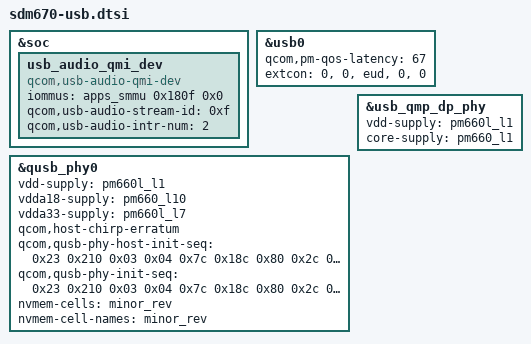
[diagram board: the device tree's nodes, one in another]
/*
 * Copyright (c) 2017-2018, The Linux Foundation. All rights reserved.
 *
 * This program is free software; you can redistribute it and/or modify
 * it under the terms of the GNU General Public License version 2 and
 * only version 2 as published by the Free Software Foundation.
 *
 * This program is distributed in the hope that it will be useful,
 * but WITHOUT ANY WARRANTY; without even the implied warranty of
 * MERCHANTABILITY or FITNESS FOR A PARTICULAR PURPOSE.  See the
 * GNU General Public License for more details.
 */

#include "sdm845-670-usb-common.dtsi"

&soc {
	/delete-node/ ssusb@a800000;
	/delete-node/ qusb@88e3000;
	/delete-node/ ssphy@88eb000;
	/delete-node/ usb_audio_qmi_dev;
	usb_audio_qmi_dev {
		compatible = "qcom,usb-audio-qmi-dev";
		iommus = <&apps_smmu 0x180f 0x0>;
		qcom,usb-audio-stream-id = <0xf>;
		qcom,usb-audio-intr-num = <2>;
	};
};

&usb0 {
	qcom,pm-qos-latency = <67>; /* CPU WFI latency + 1 */
	extcon = <0>, <0>, <&eud>, <0>, <0>;
};

&qusb_phy0 {
	vdd-supply = <&pm660l_l1>;
	vdda18-supply = <&pm660_l10>;
	vdda33-supply = <&pm660l_l7>;
	qcom,host-chirp-erratum;
	qcom,qusb-phy-host-init-seq =
			/* <value reg_offset> */
			   <0x23 0x210 /* PWR_CTRL1 */
			    0x03 0x04  /* PLL_ANALOG_CONTROLS_TWO */
			    0x7c 0x18c /* PLL_CLOCK_INVERTERS */
			    0x80 0x2c  /* PLL_CMODE */
			    0x0a 0x184 /* PLL_LOCK_DELAY */
			    0x19 0xb4  /* PLL_DIGITAL_TIMERS_TWO */
			    0x40 0x194 /* PLL_BIAS_CONTROL_1 */
			    0x20 0x198 /* PLL_BIAS_CONTROL_2 */
			    0x21 0x214 /* PWR_CTRL2 */
			    0x08 0x220 /* IMP_CTRL1 */
			    0x58 0x224 /* IMP_CTRL2 */
			    0x45 0x240 /* TUNE1 */
			    0x29 0x244 /* TUNE2 */
			    0xca 0x248 /* TUNE3 */
			    0x04 0x24c /* TUNE4 */
			    0x03 0x250 /* TUNE5 */
			    0x00 0x23c /* CHG_CTRL2 */
			    0x22 0x210>; /* PWR_CTRL1 */
	qcom,qusb-phy-init-seq =
			/* <value reg_offset> */
			   <0x23 0x210 /* PWR_CTRL1 */
			    0x03 0x04  /* PLL_ANALOG_CONTROLS_TWO */
			    0x7c 0x18c /* PLL_CLOCK_INVERTERS */
			    0x80 0x2c  /* PLL_CMODE */
			    0x0a 0x184 /* PLL_LOCK_DELAY */
			    0x19 0xb4  /* PLL_DIGITAL_TIMERS_TWO */
			    0x40 0x194 /* PLL_BIAS_CONTROL_1 */
			    0x20 0x198 /* PLL_BIAS_CONTROL_2 */
			    0x21 0x214 /* PWR_CTRL2 */
			    0x08 0x220 /* IMP_CTRL1 */
			    0x58 0x224 /* IMP_CTRL2 */
			    0x45 0x240 /* TUNE1 */
			    0x29 0x244 /* TUNE2 */
			    0xca 0x248 /* TUNE3 */
			    0x04 0x24c /* TUNE4 */
			    0x03 0x250 /* TUNE5 */
			    0x00 0x23c /* CHG_CTRL2 */
			    0x22 0x210>; /* PWR_CTRL1 */
	nvmem-cells = <&minor_rev>;
	nvmem-cell-names = "minor_rev";
};

&usb_qmp_dp_phy {
	vdd-supply = <&pm660l_l1>; /* 0.88v */
	core-supply = <&pm660_l1>; /* 1.2v */
};
